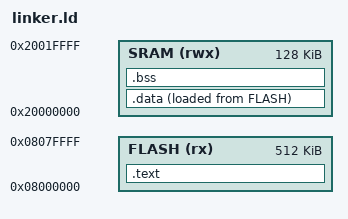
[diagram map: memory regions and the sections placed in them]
MEMORY
{
    FLASH (rx)  : ORIGIN = 0x08000000, LENGTH = 512K
    SRAM  (rwx) : ORIGIN = 0x20000000, LENGTH = 128K
}

_estack = ORIGIN(SRAM) + LENGTH(SRAM);

ENTRY(Reset_Handler)

SECTIONS
{
    .text : {
        KEEP(*(.vectors))
        *(.text*)
        *(.rodata*)
        . = ALIGN(4);
        _etext = .;
    } > FLASH

    /* where in flash to copy from */
    _sidata = LOADADDR(.data);
    .data : {
        _sdata = .;
        *(.data*)
        . = ALIGN(4);
        _edata = .;
    /* runs on SRAM, loaded from flash */
    } > SRAM AT > FLASH

    .bss : {
        _sbss = .;
        *(.bss*)
        . = ALIGN(4);
        _ebss = .;
    } > SRAM
}
